# ESP32C3 register map
File version: 1.0
CPU: RISC-V RV32IMC single-core 1, little endian, no MPU, FPU, 3 interrupt priority bits
Registers are 32-bit, read-write, reset 0x0 unless marked. A register's access mark holds for its fields unless they carry their own. Offsets are from the block's base; [hi:lo] are bit positions; {n}, {i} and the like mark numbered series.

## SYSTEM
Base 0x600C0000
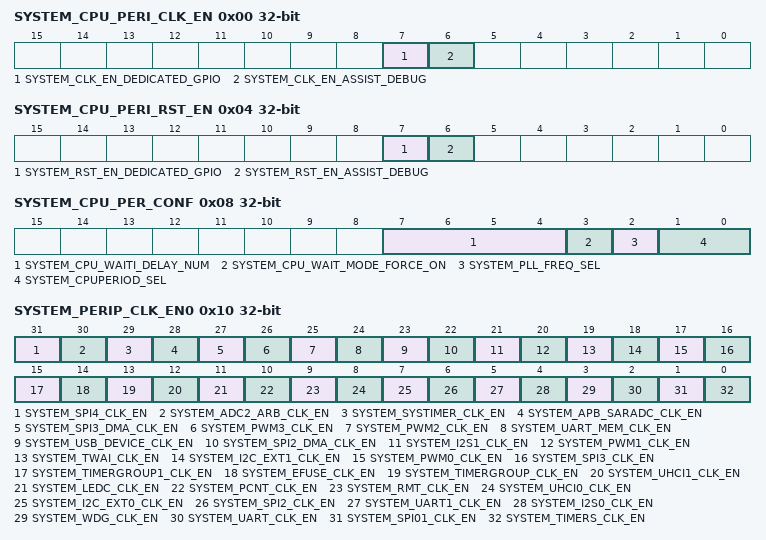
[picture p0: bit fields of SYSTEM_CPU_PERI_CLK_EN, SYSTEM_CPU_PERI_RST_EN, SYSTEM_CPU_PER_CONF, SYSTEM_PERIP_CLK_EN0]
0x00 SYSTEM_CPU_PERI_CLK_EN
  [7] SYSTEM_CLK_EN_DEDICATED_GPIO, [6] SYSTEM_CLK_EN_ASSIST_DEBUG
0x04 SYSTEM_CPU_PERI_RST_EN
  [7] SYSTEM_RST_EN_DEDICATED_GPIO, [6] SYSTEM_RST_EN_ASSIST_DEBUG
0x08 SYSTEM_CPU_PER_CONF
  [7:4] SYSTEM_CPU_WAITI_DELAY_NUM, [3] SYSTEM_CPU_WAIT_MODE_FORCE_ON, [2] SYSTEM_PLL_FREQ_SEL, [1:0] SYSTEM_CPUPERIOD_SEL
0x0C SYSTEM_MEM_PD_MASK
  [0] SYSTEM_LSLP_MEM_PD_MASK
0x10 SYSTEM_PERIP_CLK_EN0
  [31] SYSTEM_SPI4_CLK_EN, [30] SYSTEM_ADC2_ARB_CLK_EN, [29] SYSTEM_SYSTIMER_CLK_EN, [28] SYSTEM_APB_SARADC_CLK_EN, [27] SYSTEM_SPI3_DMA_CLK_EN, [26] SYSTEM_PWM3_CLK_EN, [25] SYSTEM_PWM2_CLK_EN, [24] SYSTEM_UART_MEM_CLK_EN, [23] SYSTEM_USB_DEVICE_CLK_EN, [22] SYSTEM_SPI2_DMA_CLK_EN, [21] SYSTEM_I2S1_CLK_EN, [20] SYSTEM_PWM1_CLK_EN, [19] SYSTEM_TWAI_CLK_EN, [18] SYSTEM_I2C_EXT1_CLK_EN, [17] SYSTEM_PWM0_CLK_EN, [16] SYSTEM_SPI3_CLK_EN, [15] SYSTEM_TIMERGROUP1_CLK_EN, [14] SYSTEM_EFUSE_CLK_EN, [13] SYSTEM_TIMERGROUP_CLK_EN, [12] SYSTEM_UHCI1_CLK_EN, [11] SYSTEM_LEDC_CLK_EN, [10] SYSTEM_PCNT_CLK_EN, [9] SYSTEM_RMT_CLK_EN, [8] SYSTEM_UHCI0_CLK_EN, [7] SYSTEM_I2C_EXT0_CLK_EN, [6] SYSTEM_SPI2_CLK_EN, [5] SYSTEM_UART1_CLK_EN, [4] SYSTEM_I2S0_CLK_EN, [3] SYSTEM_WDG_CLK_EN, [2] SYSTEM_UART_CLK_EN, [1] SYSTEM_SPI01_CLK_EN, [0] SYSTEM_TIMERS_CLK_EN
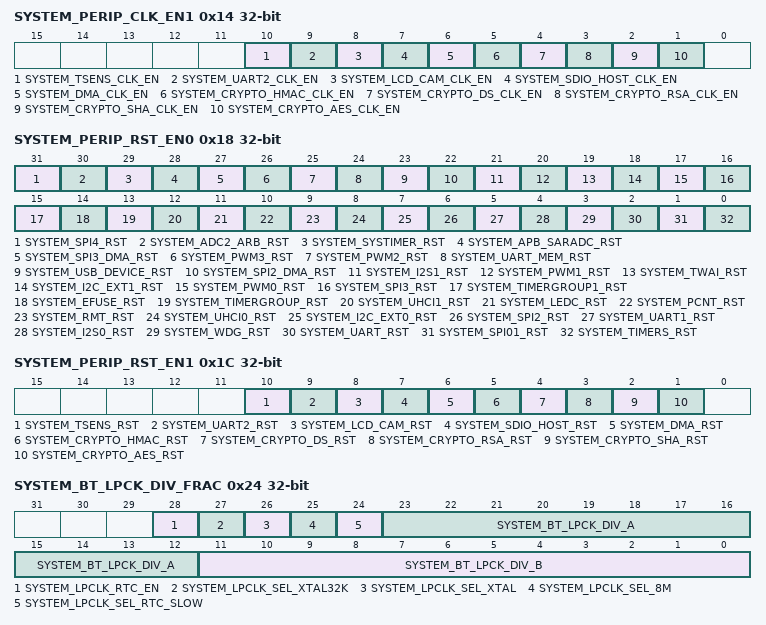
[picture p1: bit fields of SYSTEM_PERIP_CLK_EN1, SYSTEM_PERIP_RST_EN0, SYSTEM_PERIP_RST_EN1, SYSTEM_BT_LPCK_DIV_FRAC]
0x14 SYSTEM_PERIP_CLK_EN1
  [10] SYSTEM_TSENS_CLK_EN, [9] SYSTEM_UART2_CLK_EN, [8] SYSTEM_LCD_CAM_CLK_EN, [7] SYSTEM_SDIO_HOST_CLK_EN, [6] SYSTEM_DMA_CLK_EN, [5] SYSTEM_CRYPTO_HMAC_CLK_EN, [4] SYSTEM_CRYPTO_DS_CLK_EN, [3] SYSTEM_CRYPTO_RSA_CLK_EN, [2] SYSTEM_CRYPTO_SHA_CLK_EN, [1] SYSTEM_CRYPTO_AES_CLK_EN
0x18 SYSTEM_PERIP_RST_EN0
  [31] SYSTEM_SPI4_RST, [30] SYSTEM_ADC2_ARB_RST, [29] SYSTEM_SYSTIMER_RST, [28] SYSTEM_APB_SARADC_RST, [27] SYSTEM_SPI3_DMA_RST, [26] SYSTEM_PWM3_RST, [25] SYSTEM_PWM2_RST, [24] SYSTEM_UART_MEM_RST, [23] SYSTEM_USB_DEVICE_RST, [22] SYSTEM_SPI2_DMA_RST, [21] SYSTEM_I2S1_RST, [20] SYSTEM_PWM1_RST, [19] SYSTEM_TWAI_RST, [18] SYSTEM_I2C_EXT1_RST, [17] SYSTEM_PWM0_RST, [16] SYSTEM_SPI3_RST, [15] SYSTEM_TIMERGROUP1_RST, [14] SYSTEM_EFUSE_RST, [13] SYSTEM_TIMERGROUP_RST, [12] SYSTEM_UHCI1_RST, [11] SYSTEM_LEDC_RST, [10] SYSTEM_PCNT_RST, [9] SYSTEM_RMT_RST, [8] SYSTEM_UHCI0_RST, [7] SYSTEM_I2C_EXT0_RST, [6] SYSTEM_SPI2_RST, [5] SYSTEM_UART1_RST, [4] SYSTEM_I2S0_RST, [3] SYSTEM_WDG_RST, [2] SYSTEM_UART_RST, [1] SYSTEM_SPI01_RST, [0] SYSTEM_TIMERS_RST
0x1C SYSTEM_PERIP_RST_EN1
  [10] SYSTEM_TSENS_RST, [9] SYSTEM_UART2_RST, [8] SYSTEM_LCD_CAM_RST, [7] SYSTEM_SDIO_HOST_RST, [6] SYSTEM_DMA_RST, [5] SYSTEM_CRYPTO_HMAC_RST, [4] SYSTEM_CRYPTO_DS_RST, [3] SYSTEM_CRYPTO_RSA_RST, [2] SYSTEM_CRYPTO_SHA_RST, [1] SYSTEM_CRYPTO_AES_RST
0x20 SYSTEM_BT_LPCK_DIV_INT
  [11:0] SYSTEM_BT_LPCK_DIV_NUM
0x24 SYSTEM_BT_LPCK_DIV_FRAC
  [28] SYSTEM_LPCLK_RTC_EN, [27] SYSTEM_LPCLK_SEL_XTAL32K, [26] SYSTEM_LPCLK_SEL_XTAL, [25] SYSTEM_LPCLK_SEL_8M, [24] SYSTEM_LPCLK_SEL_RTC_SLOW, [23:12] SYSTEM_BT_LPCK_DIV_A, [11:0] SYSTEM_BT_LPCK_DIV_B
{0x28+4i} SYSTEM_CPU_INTR_FROM_CPU_{i} (i=0..3)
  [0] SYSTEM_CPU_INTR_FROM_CPU_{i}
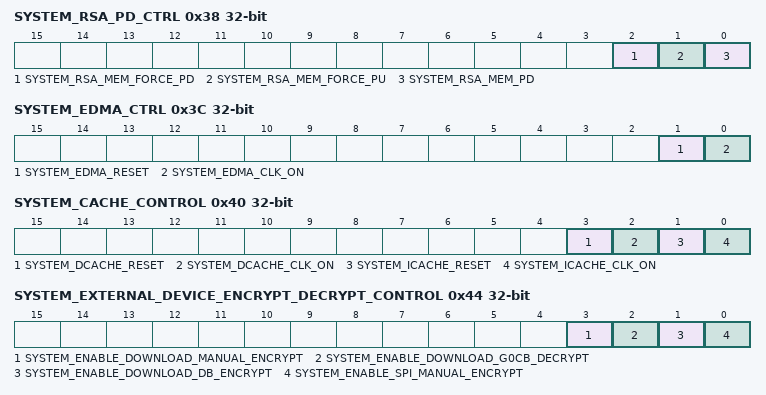
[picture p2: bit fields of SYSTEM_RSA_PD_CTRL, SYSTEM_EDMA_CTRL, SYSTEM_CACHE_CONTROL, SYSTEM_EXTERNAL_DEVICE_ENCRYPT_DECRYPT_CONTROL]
0x38 SYSTEM_RSA_PD_CTRL
  [2] SYSTEM_RSA_MEM_FORCE_PD, [1] SYSTEM_RSA_MEM_FORCE_PU, [0] SYSTEM_RSA_MEM_PD
0x3C SYSTEM_EDMA_CTRL
  [1] SYSTEM_EDMA_RESET, [0] SYSTEM_EDMA_CLK_ON
0x40 SYSTEM_CACHE_CONTROL
  [3] SYSTEM_DCACHE_RESET, [2] SYSTEM_DCACHE_CLK_ON, [1] SYSTEM_ICACHE_RESET, [0] SYSTEM_ICACHE_CLK_ON
0x44 SYSTEM_EXTERNAL_DEVICE_ENCRYPT_DECRYPT_CONTROL
  [3] SYSTEM_ENABLE_DOWNLOAD_MANUAL_ENCRYPT, [2] SYSTEM_ENABLE_DOWNLOAD_G0CB_DECRYPT, [1] SYSTEM_ENABLE_DOWNLOAD_DB_ENCRYPT, [0] SYSTEM_ENABLE_SPI_MANUAL_ENCRYPT
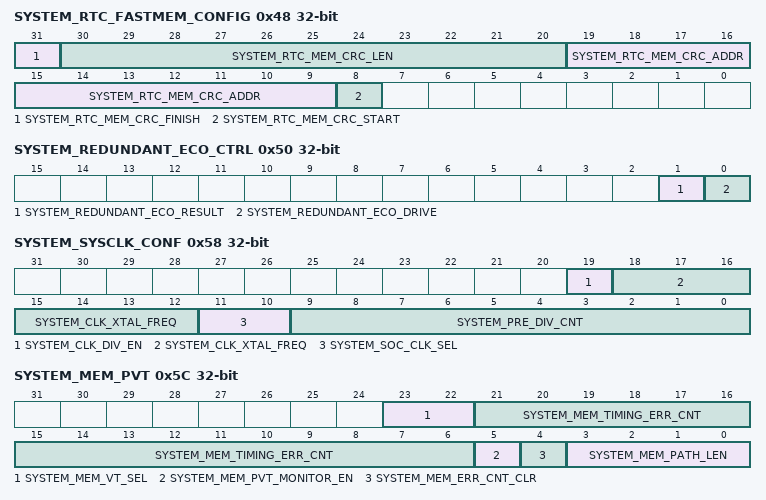
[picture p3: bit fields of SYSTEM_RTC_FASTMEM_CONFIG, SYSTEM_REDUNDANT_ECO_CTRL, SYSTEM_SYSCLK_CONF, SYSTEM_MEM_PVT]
0x48 SYSTEM_RTC_FASTMEM_CONFIG access per field
  [31] SYSTEM_RTC_MEM_CRC_FINISH ro, [30:20] SYSTEM_RTC_MEM_CRC_LEN rw, [19:9] SYSTEM_RTC_MEM_CRC_ADDR rw, [8] SYSTEM_RTC_MEM_CRC_START rw
0x4C SYSTEM_RTC_FASTMEM_CRC ro
  [31:0] SYSTEM_RTC_MEM_CRC_RES
0x50 SYSTEM_REDUNDANT_ECO_CTRL access per field
  [1] SYSTEM_REDUNDANT_ECO_RESULT ro, [0] SYSTEM_REDUNDANT_ECO_DRIVE rw
0x54 SYSTEM_CLOCK_GATE
  [0] SYSTEM_CLK_EN
0x58 SYSTEM_SYSCLK_CONF access per field
  [19] SYSTEM_CLK_DIV_EN ro, [18:12] SYSTEM_CLK_XTAL_FREQ ro, [11:10] SYSTEM_SOC_CLK_SEL rw, [9:0] SYSTEM_PRE_DIV_CNT rw
0x5C SYSTEM_MEM_PVT access per field
  [23:22] SYSTEM_MEM_VT_SEL rw, [21:6] SYSTEM_MEM_TIMING_ERR_CNT ro, [5] SYSTEM_MEM_PVT_MONITOR_EN rw, [4] SYSTEM_MEM_ERR_CNT_CLR wo, [3:0] SYSTEM_MEM_PATH_LEN rw
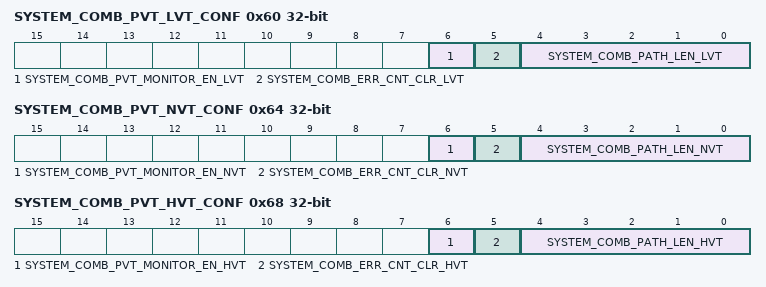
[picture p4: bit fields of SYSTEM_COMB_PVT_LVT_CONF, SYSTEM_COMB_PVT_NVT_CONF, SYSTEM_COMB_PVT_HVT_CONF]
0x60 SYSTEM_COMB_PVT_LVT_CONF access per field
  [6] SYSTEM_COMB_PVT_MONITOR_EN_LVT rw, [5] SYSTEM_COMB_ERR_CNT_CLR_LVT wo, [4:0] SYSTEM_COMB_PATH_LEN_LVT rw
0x64 SYSTEM_COMB_PVT_NVT_CONF access per field
  [6] SYSTEM_COMB_PVT_MONITOR_EN_NVT rw, [5] SYSTEM_COMB_ERR_CNT_CLR_NVT wo, [4:0] SYSTEM_COMB_PATH_LEN_NVT rw
0x68 SYSTEM_COMB_PVT_HVT_CONF access per field
  [6] SYSTEM_COMB_PVT_MONITOR_EN_HVT rw, [5] SYSTEM_COMB_ERR_CNT_CLR_HVT wo, [4:0] SYSTEM_COMB_PATH_LEN_HVT rw
{0x6C+0xC*i} SYSTEM_COMB_PVT_ERR_LVT_SITE{i} ro (i=0..3)
  [15:0] SYSTEM_COMB_TIMING_ERR_CNT_LVT_SITE{i}
{0x70+0xC*i} SYSTEM_COMB_PVT_ERR_NVT_SITE{i} ro (i=0..3)
  [15:0] SYSTEM_COMB_TIMING_ERR_CNT_NVT_SITE{i}
{0x74+0xC*i} SYSTEM_COMB_PVT_ERR_HVT_SITE{i} ro (i=0..3)
  [15:0] SYSTEM_COMB_TIMING_ERR_CNT_HVT_SITE{i}
0xFFC SYSTEM_DATE
  [27:0] SYSTEM_DATE
